VERSION ""

NS_ :

BS_:

BU_:

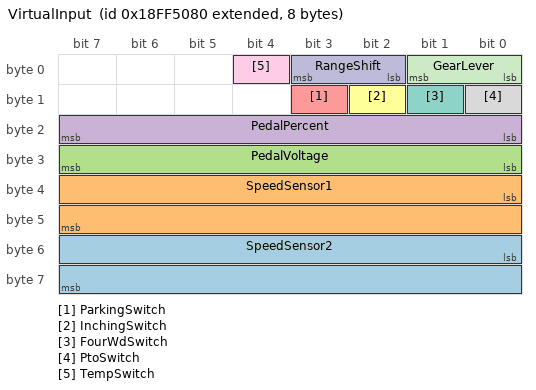
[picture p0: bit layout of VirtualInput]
BO_ 2566869120 VirtualInput: 8 Vector__XXX
 SG_ SpeedSensor2 : 48|16@1+ (1,0) [0|65535] "RPM" Vector__XXX
 SG_ SpeedSensor1 : 32|16@1+ (1,0) [0|65535] "RPM" Vector__XXX
 SG_ PedalVoltage : 24|8@1+ (1,0) [0|255] "" Vector__XXX
 SG_ PedalPercent : 16|8@1+ (1,0) [0|100] "%" Vector__XXX
 SG_ ParkingSwitch : 11|1@1+ (1,0) [0|1] "" Vector__XXX
 SG_ InchingSwitch : 10|1@1+ (1,0) [0|1] "" Vector__XXX
 SG_ FourWdSwitch : 9|1@1+ (1,0) [0|1] "" Vector__XXX
 SG_ PtoSwitch : 8|1@1+ (1,0) [0|1] "" Vector__XXX
 SG_ TempSwitch : 4|1@1+ (1,0) [0|1] "" Vector__XXX
 SG_ RangeShift : 2|2@1+ (1,0) [0|3] "" Vector__XXX
 SG_ GearLever : 0|2@1+ (1,0) [0|3] "" Vector__XXX

CM_ BO_ 2566869120 "Q3-self-defined. Extended CAN ID 0x18FF5080 (J1939 Proprietary B, PGN 0xFF50, SA 0x80). PC->TCU virtual input for Simulation Mode (Operating Mode 0001b). Heartbeat period 50ms (provider enforced). Intel @1+ variant. Real TCU may not accept this ID; effective only in Simulator/VirtualCanBus.";
CM_ SG_ 2566869120 GearLever "Byte 0 bits 1..0. Intel start=0 = signal LSB.";
CM_ SG_ 2566869120 RangeShift "Byte 0 bits 3..2. Intel start=2 = signal LSB.";
CM_ SG_ 2566869120 PedalPercent "Byte 2. Intel start=16 = Byte 2 bit 0 (signal LSB). Unit percent, 0..100.";
CM_ SG_ 2566869120 PedalVoltage "Byte 3. Raw ADC 0..255 (no scaling).";
CM_ SG_ 2566869120 SpeedSensor1 "Bytes 4~5 little-endian. Intel start=32 = Byte 4 bit 0 (signal LSB). Unit RPM, 0..65535.";
CM_ SG_ 2566869120 SpeedSensor2 "Bytes 6~7 little-endian. Intel start=48 = Byte 6 bit 0 (signal LSB). Unit RPM, 0..65535.";

VAL_ 2566869120 GearLever 0 "None" 1 "Neutral" 2 "Forward" 3 "Reverse" ;
VAL_ 2566869120 RangeShift 0 "None" 1 "First" 2 "Second" 3 "Third" ;
